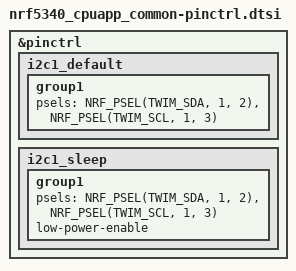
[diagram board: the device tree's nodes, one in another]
/*
 * Copyright (c) 2025 Daniel Kampert
 *
 * SPDX-License-Identifier: Apache-2.0
 */

&pinctrl {
    i2c1_default: i2c1_default {
        group1 {
            psels = <NRF_PSEL(TWIM_SDA, 1, 2)>,
                    <NRF_PSEL(TWIM_SCL, 1, 3)>;
        };
    };

    i2c1_sleep: i2c1_sleep {
        group1 {
            psels = <NRF_PSEL(TWIM_SDA, 1, 2)>,
                    <NRF_PSEL(TWIM_SCL, 1, 3)>;
            low-power-enable;
        };
    };
};
